# GT32U2086 register map
Vendor: FPTTelecom
Registers are 32-bit, read-write, reset 0x0 unless marked. A register's access mark holds for its fields unless they carry their own. Offsets are from the block's base; [hi:lo] are bit positions.

## UART0 — UART0 - UNIVERSAL ASYNCHRONOUS RECEIVER TRANSMITTER UART0 : 0x440D0000 - 0x440DFFFF (64 KB)
Base 0x440D0000
Same registers: UART1 0x440E0000, UART2 0x50050000, UART3 0x50060000, UART4 0x50070000
0x00 RBR ro (RBR_DLL_THR view) — Receiver Buffer Register when DLAB=0 and the CPU reads
  [8:0] RDATA — 9-bit receive data in bits [8:0]
0x00 DLL (RBR_DLL_THR view) — Divisor Latch LSB when DLAB=1
  [7:0] DLSB — Low 8 bits of the baud-rate divisor in bits [7:0]
0x00 THR wo (RBR_DLL_THR view) — Transmitter Holding Register when DLAB=0 and CPU write
  [8:0] TDATA — 9-bit transmit data in bits [8:0]
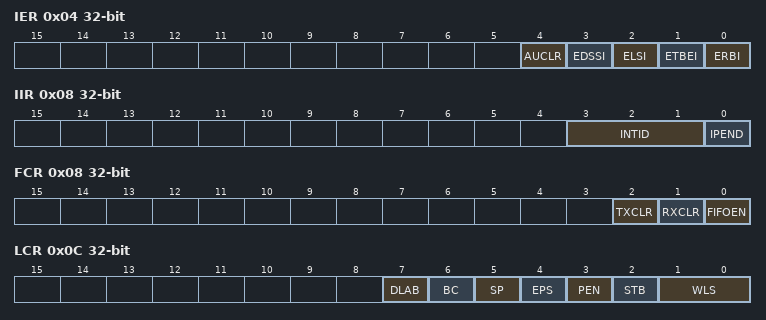
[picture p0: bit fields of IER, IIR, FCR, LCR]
0x04 IER (IER_DLM view) — Interrupt Enable Register when DLAB=0
  [4] AUCLR — Interrupt clearing: 0=hardware auto-clear, 1=software acknowledge by reading IIR
  [3] EDSSI — Enable modem-status interrupt
  [2] ELSI — Enable receiver-line-status interrupt
  [1] ETBEI — Enable transmitter-holding-register full interrupt
  [0] ERBI — Enable received-data-available interrupt
0x04 DLM (IER_DLM view) — Divisor Latch MSB when DLAB=1
  [7:0] DLSM — High 8 bits of the baud-rate divisor in bits [7:0]
0x08 IIR ro (IIR_FCR view) — Interrupt Identification Register
  [3:1] INTID — Interrupt ID: 0=none, 1=TX full, 2=RX ready, 3=line status, 4=character timeout, 5=DMA TX done, 6=DMA RX done
  [0] IPEND — Interrupt-pending status: 1=pending, 0=none
0x08 FCR wo (IIR_FCR view) — FIFO Control Register
  [2] TXCLR — Write 1 to clear the TX FIFO; self-clearing bit
  [1] RXCLR — Write 1 to clear the RX FIFO; self-clearing bit
  [0] FIFOEN — FIFO mode disable: 0=FIFOs enabled, 1=non-FIFO mode and counters cleared; clear before programming other FCR bits
0x0C LCR — Line Control Register bit[1:0] WLS | bit[2] STB | bit[3] PEN | bit[4] EPS | bit[5] SP | bit[6] BC | bit[7] DLAB
  [7] DLAB — Enable DLL and DLM access at the shared addresses
  [6] BC — Control break transmission
  [5] SP — Enable stick parity
  [4] EPS — Select even parity when PEN=1
  [3] PEN — Enable parity
  [2] STB — Select the number of stop bits
  [1:0] WLS — Select data length: 00=5, 01=6, 10=7, 11=8 bit
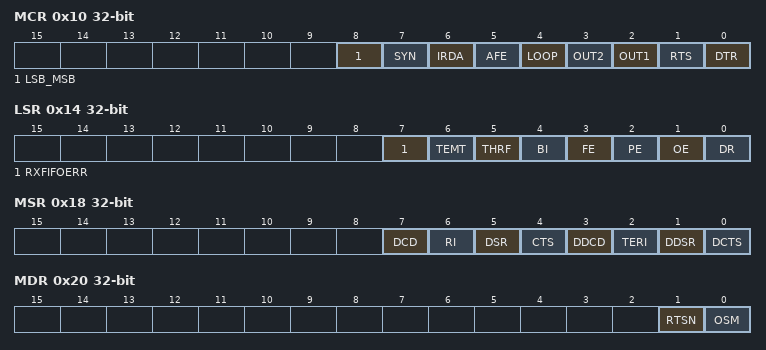
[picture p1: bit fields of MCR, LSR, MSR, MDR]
0x10 MCR — Modem Control Register bit[0] DTR | bit[1] RTS | bit[2] OUT1 | bit[3] OUT2 | bit[4] LOOP | bit[5] AFE | bit[6] IRDA | bit[7] SYN | bit[8] LSB_MSB
  [8] LSB_MSB — Select LSB-first or MSB-first data order
  [7] SYN — Enable synchronous transfer mode
  [6] IRDA — Enable IrDA mode
  [5] AFE — Enable automatic flow control
  [4] LOOP — Enable internal loopback mode
  [3] OUT2 — Modem output OUT2
  [2] OUT1 — Modem output OUT1
  [1] RTS — RTS control: 0=force active level, 1=hardware automatic control
  [0] DTR — Control Data Terminal Ready
0x14 LSR ro — Line Status Register bit[0] DR | bit[1] OE | bit[2] PE | bit[3] FE | bit[4] BI | bit[5] THRF | bit[6] TEMT | bit[7] RXFIFOERR
  [7] RXFIFOERR — RX FIFO contains erroneous data
  [6] TEMT — Transmitter completely empty
  [5] THRF — Transmit holding register/FIFO full; 0 means new data may be written
  [4] BI — Break detected
  [3] FE — Framing error
  [2] PE — Parity error
  [1] OE — Receive-data overrun error
  [0] DR — Receive data available
0x18 MSR ro — Modem Status Register bit[0] DCTS | bit[1] DDSR | bit[2] TERI | bit[3] DDCD | bit[4] CTS | bit[5] DSR | bit[6] RI | bit[7] DCD
  [7] DCD — Data Carrier Detect status
  [6] RI — Ring Indicator status
  [5] DSR — Data Set Ready status
  [4] CTS — Clear To Send status
  [3] DDCD — DCD state changed
  [2] TERI — RI falling edge detected
  [1] DDSR — DSR state changed
  [0] DCTS — CTS state changed
0x1C SCR — Scratch Pad Register bit[7:0] SCR
  [7:0] SCR — 8-bit scratch data; does not affect UART operation
0x20 MDR — Mode Definition Register bit[0] OSM | bit[1] RTSN
  [1] RTSN — Select the active level of RTS
  [0] OSM — Select oversampling: 0=x16, 1=x8
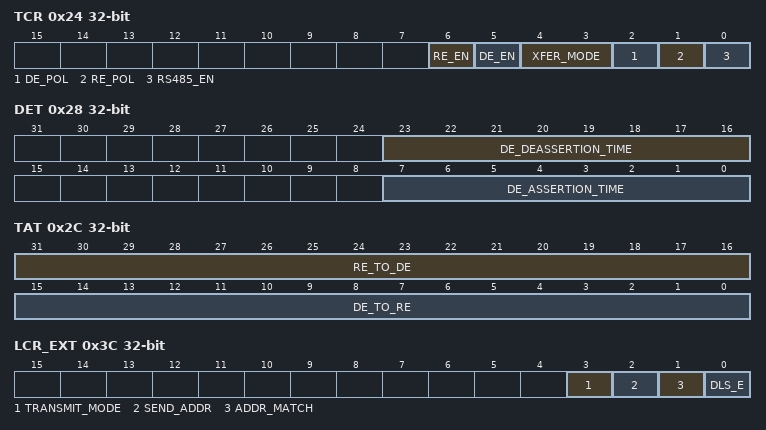
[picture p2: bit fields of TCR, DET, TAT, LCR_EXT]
0x24 TCR — Transceiver Control Register bit[0] RS485_EN | bit[1] RE_POL | bit[2] DE_POL | bit[4:3] XFER_MODE | bit[5] DE_EN | bit[6] RE_EN
  [6] RE_EN — Control the Receiver Enable output
  [5] DE_EN — Control the Driver Enable output
  [4:3] XFER_MODE — Select the RS485 transfer mode in bits [4:3]
  [2] DE_POL — Select Driver Enable polarity
  [1] RE_POL — Select Receiver Enable polarity
  [0] RS485_EN — Enable RS485 mode
0x28 DET — Driver Output Enable Timing Register bit[7:0] DE_ASSERTION_TIME | bit[23:16] DE_DEASSERTION_TIME
  [23:16] DE_DEASSERTION_TIME — DE deassertion time in bits [23:16]
  [7:0] DE_ASSERTION_TIME — DE assertion time in bits [7:0]
0x2C TAT — Turnaround Timing Register bit[15:0] DE_TO_RE | bit[31:16] RE_TO_DE
  [31:16] RE_TO_DE — RE-to-DE transition time in bits [31:16]
  [15:0] DE_TO_RE — DE-to-RE transition time in bits [15:0]
0x30 DLF — Divisor Latch Fraction Register bit[3:0] DLF
  [3:0] DLF — 4-bit fractional part of the baud-rate divisor in bits [3:0]
0x34 RAR — Receive Address Register bit[7:0] ADDR
  [7:0] ADDR — Receive address in bits [7:0]
0x38 TAR — Transmit Address Register bit[7:0] ADDR
  [7:0] ADDR — Transmit address in bits [7:0]
0x3C LCR_EXT — Line Extended Control Register bit[0] DLS_E | bit[1] ADDR_MATCH | bit[2] SEND_ADDR | bit[3] TRANSMIT_MODE
  [3] TRANSMIT_MODE — 9-bit TX mode: 0=8-bit THR with separate address control, 1=9-bit THR
  [2] SEND_ADDR — Request transmission of the address byte
  [1] ADDR_MATCH — Enable address matching in 9-bit mode
  [0] DLS_E — Extend the data length to 9 bits
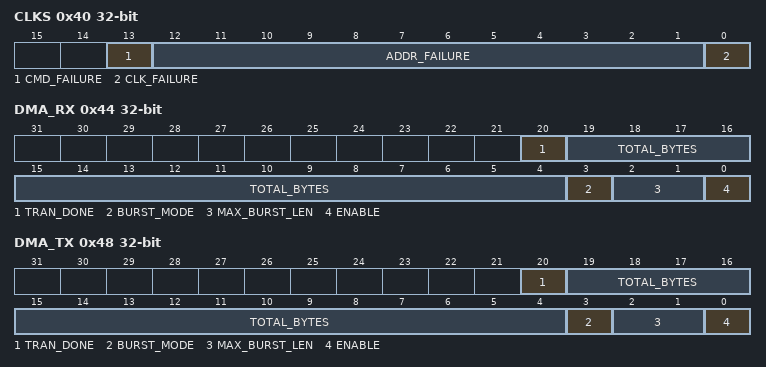
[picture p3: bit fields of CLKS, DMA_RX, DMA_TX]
0x40 CLKS ro — Clock Status Register bit[0] CLK_FAILURE | bit[12:1] ADDR_FAILURE | bit[13] CMD_FAILURE; read-to-clear
  [13] CMD_FAILURE — Failed command type: 0=write, 1=read
  [12:1] ADDR_FAILURE — Address of the first APB command affected by the clock failure
  [0] CLK_FAILURE — Clock-error flag
0x44 DMA_RX — UART DMA RX control; TRAN_DONE is cleared by reading IIR
  [20] TRAN_DONE — RX transfer complete; read IIR to acknowledge
  [19:4] TOTAL_BYTES — Number of received UART data bytes
  [3] BURST_MODE — 0=single, 1=burst
  [2:1] MAX_BURST_LEN — Singles per burst: 0=2, 1=4, 2=8, 3=16
  [0] ENABLE — Enable RX DMA handshaking
0x48 DMA_TX — UART DMA TX control; TRAN_DONE is cleared by reading IIR
  [20] TRAN_DONE — TX transfer complete; read IIR to acknowledge
  [19:4] TOTAL_BYTES — Number of transmitted UART data bytes
  [3] BURST_MODE — 0=single, 1=burst
  [2:1] MAX_BURST_LEN — Singles per burst: 0=2, 1=4, 2=8, 3=16
  [0] ENABLE — Enable TX DMA handshaking
